AUTOSAR XML (schema 4-0-3)
package /CLBR_Code_pkg/CLBR_Code_swc
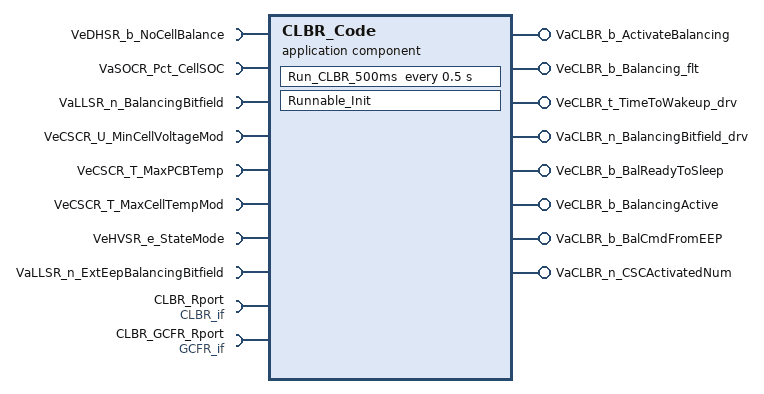
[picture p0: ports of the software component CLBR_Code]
  application sw component type CLBR_Code
    8 x require port:
      VeDHSR_b_NoCellBalance: nonqueued-receiver-com-spec{data-element=VeDHSR_b_NoCellBalance, init-value=0}, required-interface=VeDHSR_b_NoCellBalance
      VaSOCR_Pct_CellSOC: nonqueued-receiver-com-spec{data-element=VaSOCR_Pct_CellSOC, init-value=96 x 0}, required-interface=VaSOCR_Pct_CellSOC
      VaLLSR_n_BalancingBitfield: nonqueued-receiver-com-spec{data-element=VaLLSR_n_BalancingBitfield, init-value=14 x 0}, required-interface=VaLLSR_n_BalancingBitfield
      VeCSCR_U_MinCellVoltageMod: nonqueued-receiver-com-spec{data-element=VeCSCR_U_MinCellVoltageMod, init-value=0}, required-interface=VeCSCR_U_MinCellVoltageMod
      VeCSCR_T_MaxPCBTemp: nonqueued-receiver-com-spec{data-element=VeCSCR_T_MaxPCBTemp, init-value=0}, required-interface=VeCSCR_T_MaxPCBTemp
      VeCSCR_T_MaxCellTempMod: nonqueued-receiver-com-spec{data-element=VeCSCR_T_MaxCellTempMod, init-value=0}, required-interface=VeCSCR_T_MaxCellTempMod
      VeHVSR_e_StateMode: nonqueued-receiver-com-spec{data-element=VeHVSR_e_StateMode, init-value=CeHVSR_e_StateModeReserved}, required-interface=VeHVSR_e_StateMode
      VaLLSR_n_ExtEepBalancingBitfield: nonqueued-receiver-com-spec{data-element=VaLLSR_n_ExtEepBalancingBitfield, init-value=14 x 0}, required-interface=VaLLSR_n_ExtEepBalancingBitfield
    8 x provide port:
      VaCLBR_b_ActivateBalancing: nonqueued-sender-com-spec{data-element=VaCLBR_b_ActivateBalancing, init-value=96 x 0}, provided-interface=VaCLBR_b_ActivateBalancing
      VeCLBR_b_Balancing_flt: nonqueued-sender-com-spec{data-element=VeCLBR_b_Balancing_flt, init-value=0}, provided-interface=VeCLBR_b_Balancing_flt
      VeCLBR_t_TimeToWakeup_drv: nonqueued-sender-com-spec{data-element=VeCLBR_t_TimeToWakeup_drv, init-value=0}, provided-interface=VeCLBR_t_TimeToWakeup_drv
      VaCLBR_n_BalancingBitfield_drv: nonqueued-sender-com-spec{data-element=VaCLBR_n_BalancingBitfield_drv, init-value=14 x 0}, provided-interface=VaCLBR_n_BalancingBitfield_drv
      VeCLBR_b_BalReadyToSleep: nonqueued-sender-com-spec{data-element=VeCLBR_b_BalReadyToSleep, init-value=0}, provided-interface=VeCLBR_b_BalReadyToSleep
      VeCLBR_b_BalancingActive: nonqueued-sender-com-spec{data-element=VeCLBR_b_BalancingActive, init-value=0}, provided-interface=VeCLBR_b_BalancingActive
      VaCLBR_b_BalCmdFromEEP: nonqueued-sender-com-spec{data-element=VaCLBR_b_BalCmdFromEEP, init-value=96 x 0}, provided-interface=VaCLBR_b_BalCmdFromEEP
      VaCLBR_n_CSCActivatedNum: nonqueued-sender-com-spec{data-element=VaCLBR_n_CSCActivatedNum, init-value=8 x 0}, provided-interface=VaCLBR_n_CSCActivatedNum
    require port CLBR_Rport: required-interface=CLBR_if
    require port CLBR_GCFR_Rport: required-interface=GCFR_if
    behavior CLBR_Code: data-type-mapping=[CLBR_CodeDataTypeMappingsSet, WorkingDataTypeMappingsSet], handle-termination-and-restart=NO-SUPPORT
      timing event Event_Run_CLBR_500ms: start-on-event=Run_CLBR_500ms, period=0.5
      runnable Runnable_Init: symbol=CLBR_Code_Init
        data-send-points:
          access OUT_VaCLBR_n_BalancingBitfield_drv_VaCLBR_n_B_c2f0339c135420ab: accessed-variable=VaCLBR_n_BalancingBitfield_drv.VaCLBR_n_BalancingBitfield_drv
          access OUT_VaCLBR_b_BalCmdFromEEP_VaCLBR_b_BalCmdFromEEP: accessed-variable=VaCLBR_b_BalCmdFromEEP.VaCLBR_b_BalCmdFromEEP
          access OUT_VaCLBR_n_CSCActivatedNum_VaCLBR_n_CSCActivatedNum: accessed-variable=VaCLBR_n_CSCActivatedNum.VaCLBR_n_CSCActivatedNum
      runnable Run_CLBR_500ms
        data-read-access:
          8 x access:
            IN_VaLLSR_n_BalancingBitfield_VaLLSR_n_BalancingBitfield: accessed-variable=VaLLSR_n_BalancingBitfield.VaLLSR_n_BalancingBitfield
            IN_VaLLSR_n_ExtEepBalancingBitfield_VaLLSR_n_fa9eb7aaa6c59263: accessed-variable=VaLLSR_n_ExtEepBalancingBitfield.VaLLSR_n_ExtEepBalancingBitfield
            IN_VaSOCR_Pct_CellSOC_VaSOCR_Pct_CellSOC: accessed-variable=VaSOCR_Pct_CellSOC.VaSOCR_Pct_CellSOC
            IN_VeCSCR_T_MaxCellTempMod_VeCSCR_T_MaxCellTempMod: accessed-variable=VeCSCR_T_MaxCellTempMod.VeCSCR_T_MaxCellTempMod
            IN_VeCSCR_T_MaxPCBTemp_VeCSCR_T_MaxPCBTemp: accessed-variable=VeCSCR_T_MaxPCBTemp.VeCSCR_T_MaxPCBTemp
            IN_VeCSCR_U_MinCellVoltageMod_VeCSCR_U_MinCellVoltageMod: accessed-variable=VeCSCR_U_MinCellVoltageMod.VeCSCR_U_MinCellVoltageMod
            IN_VeDHSR_b_NoCellBalance_VeDHSR_b_NoCellBalance: accessed-variable=VeDHSR_b_NoCellBalance.VeDHSR_b_NoCellBalance
            IN_VeHVSR_e_StateMode_VeHVSR_e_StateMode: accessed-variable=VeHVSR_e_StateMode.VeHVSR_e_StateMode
        data-send-points:
          8 x access:
            OUT_VaCLBR_b_ActivateBalancing_VaCLBR_b_ActivateBalancing: accessed-variable=VaCLBR_b_ActivateBalancing.VaCLBR_b_ActivateBalancing
            OUT_VeCLBR_b_Balancing_flt_VeCLBR_b_Balancing_flt: accessed-variable=VeCLBR_b_Balancing_flt.VeCLBR_b_Balancing_flt
            OUT_VeCLBR_t_TimeToWakeup_drv_VeCLBR_t_TimeToWakeup_drv: accessed-variable=VeCLBR_t_TimeToWakeup_drv.VeCLBR_t_TimeToWakeup_drv
            OUT_VaCLBR_n_BalancingBitfield_drv_VaCLBR_n_B_c2f0339c135420ab: accessed-variable=VaCLBR_n_BalancingBitfield_drv.VaCLBR_n_BalancingBitfield_drv
            OUT_VeCLBR_b_BalReadyToSleep_VeCLBR_b_BalReadyToSleep: accessed-variable=VeCLBR_b_BalReadyToSleep.VeCLBR_b_BalReadyToSleep
            OUT_VeCLBR_b_BalancingActive_VeCLBR_b_BalancingActive: accessed-variable=VeCLBR_b_BalancingActive.VeCLBR_b_BalancingActive
            OUT_VaCLBR_b_BalCmdFromEEP_VaCLBR_b_BalCmdFromEEP: accessed-variable=VaCLBR_b_BalCmdFromEEP.VaCLBR_b_BalCmdFromEEP
            OUT_VaCLBR_n_CSCActivatedNum_VaCLBR_n_CSCActivatedNum: accessed-variable=VaCLBR_n_CSCActivatedNum.VaCLBR_n_CSCActivatedNum
        25 x parameter access:
          CALPRM_CLBR_Rport_KaCLBR_n_OvrdValBalBitfield: accessed-parameter=CLBR_Rport.KaCLBR_n_OvrdValBalBitfield
          CALPRM_CLBR_Rport_KaCLBR_n_TurnOffBalBitfield: accessed-parameter=CLBR_Rport.KaCLBR_n_TurnOffBalBitfield
          CALPRM_CLBR_Rport_KeCLBR_Cnt_BitFieldByteLength: accessed-parameter=CLBR_Rport.KeCLBR_Cnt_BitFieldByteLength
          CALPRM_CLBR_Rport_KeCLBR_Pct_DiffSOCThresholdCompletedCLB: accessed-parameter=CLBR_Rport.KeCLBR_Pct_DiffSOCThresholdCompletedCLB
          CALPRM_CLBR_Rport_KeCLBR_Pct_DiffSOCThresholdForCLB: accessed-parameter=CLBR_Rport.KeCLBR_Pct_DiffSOCThresholdForCLB
          CALPRM_CLBR_Rport_KeCLBR_T_ThresholdMaxTemprCSC: accessed-parameter=CLBR_Rport.KeCLBR_T_ThresholdMaxTemprCSC
          CALPRM_CLBR_Rport_KeCLBR_T_ThresholdMaxTemprCell: accessed-parameter=CLBR_Rport.KeCLBR_T_ThresholdMaxTemprCell
          CALPRM_CLBR_Rport_KeCLBR_U_NoCLB_Threshold: accessed-parameter=CLBR_Rport.KeCLBR_U_NoCLB_Threshold
          CALPRM_CLBR_Rport_KeCLBR_b_EnableCLBR: accessed-parameter=CLBR_Rport.KeCLBR_b_EnableCLBR
          CALPRM_CLBR_Rport_KeCLBR_b_OvrdCtrlBalBitfield: accessed-parameter=CLBR_Rport.KeCLBR_b_OvrdCtrlBalBitfield
          CALPRM_CLBR_Rport_KeCLBR_b_OvrdCtrlBalReadyToSleep: accessed-parameter=CLBR_Rport.KeCLBR_b_OvrdCtrlBalReadyToSleep
          CALPRM_CLBR_Rport_KeCLBR_b_OvrdCtrlBalancingActive: accessed-parameter=CLBR_Rport.KeCLBR_b_OvrdCtrlBalancingActive
          CALPRM_CLBR_Rport_KeCLBR_b_OvrdCtrlBalancingFlt: accessed-parameter=CLBR_Rport.KeCLBR_b_OvrdCtrlBalancingFlt
          CALPRM_CLBR_Rport_KeCLBR_b_OvrdCtrlTTW: accessed-parameter=CLBR_Rport.KeCLBR_b_OvrdCtrlTTW
          CALPRM_CLBR_Rport_KeCLBR_b_OvrdValBalReadyToSleep: accessed-parameter=CLBR_Rport.KeCLBR_b_OvrdValBalReadyToSleep
          CALPRM_CLBR_Rport_KeCLBR_b_OvrdValBalancingActive: accessed-parameter=CLBR_Rport.KeCLBR_b_OvrdValBalancingActive
          CALPRM_CLBR_Rport_KeCLBR_b_OvrdValBalancingFlt: accessed-parameter=CLBR_Rport.KeCLBR_b_OvrdValBalancingFlt
          CALPRM_CLBR_Rport_KeCLBR_t_BalReEvalDone: accessed-parameter=CLBR_Rport.KeCLBR_t_BalReEvalDone
          CALPRM_CLBR_Rport_KeCLBR_t_DbncCLBR: accessed-parameter=CLBR_Rport.KeCLBR_t_DbncCLBR
          CALPRM_CLBR_Rport_KeCLBR_t_DbncCompletedCLBR: accessed-parameter=CLBR_Rport.KeCLBR_t_DbncCompletedCLBR
          CALPRM_CLBR_Rport_KeCLBR_t_OvrdValTTW: accessed-parameter=CLBR_Rport.KeCLBR_t_OvrdValTTW
          CALPRM_CLBR_Rport_KeCLBR_t_SR_CLBR: accessed-parameter=CLBR_Rport.KeCLBR_t_SR_CLBR
          CALPRM_CLBR_Rport_KeCLBR_t_TimeToWakeupRTC: accessed-parameter=CLBR_Rport.KeCLBR_t_TimeToWakeupRTC
          CALPRM_CLBR_GCFR_Rport_KeGCFR_Cnt_NumberOfCSC: accessed-parameter=CLBR_GCFR_Rport.KeGCFR_Cnt_NumberOfCSC
          CALPRM_CLBR_GCFR_Rport_KeGCFR_Cnt_NumberofCells: accessed-parameter=CLBR_GCFR_Rport.KeGCFR_Cnt_NumberofCells
package /CalibrationComponents
  parameter sw component type CLBR: data-type-mapping=[CLBR_CodeDataTypeMappingsSet, WorkingDataTypeMappingsSet]
    provide port CLBR_Pport: provided-interface=CLBR_if
      provided-com-specs:
        init-value=2, parameter=KeCLBR_Pct_DiffSOCThresholdCompletedCLB
        init-value=5, parameter=KeCLBR_Pct_DiffSOCThresholdForCLB
        init-value=96, parameter=KeCLBR_T_ThresholdMaxTemprCSC
        init-value=55, parameter=KeCLBR_T_ThresholdMaxTemprCell
        init-value=3, parameter=KeCLBR_U_NoCLB_Threshold
        init-value=3, parameter=KeCLBR_t_BalReEvalDone
        init-value=1, parameter=KeCLBR_t_DbncCLBR
        init-value=0.5, parameter=KeCLBR_t_DbncCompletedCLBR
        init-value=0, parameter=KeCLBR_t_OvrdValTTW
        init-value=0.5, parameter=KeCLBR_t_SR_CLBR
        init-value=5400, parameter=KeCLBR_t_TimeToWakeupRTC
        init-value=1, parameter=KeCLBR_b_EnableCLBR
        init-value=0, parameter=KeCLBR_b_OvrdCtrlBalBitfield
        init-value=0, parameter=KeCLBR_b_OvrdCtrlBalReadyToSleep
        init-value=0, parameter=KeCLBR_b_OvrdCtrlBalancingActive
        init-value=0, parameter=KeCLBR_b_OvrdCtrlBalancingFlt
        init-value=0, parameter=KeCLBR_b_OvrdCtrlTTW
        init-value=0, parameter=KeCLBR_b_OvrdValBalReadyToSleep
        init-value=0, parameter=KeCLBR_b_OvrdValBalancingActive
        init-value=0, parameter=KeCLBR_b_OvrdValBalancingFlt
        init-value=CLBR_Pport_KaCLBR_n_OvrdValBalBitfield:14 x 0, parameter=KaCLBR_n_OvrdValBalBitfield
        init-value=CLBR_Pport_KaCLBR_n_TurnOffBalBitfield:14 x 0, parameter=KaCLBR_n_TurnOffBalBitfield
        init-value=14, parameter=KeCLBR_Cnt_BitFieldByteLength
